AUTOSAR XML (schema 314)
package /ComponentType
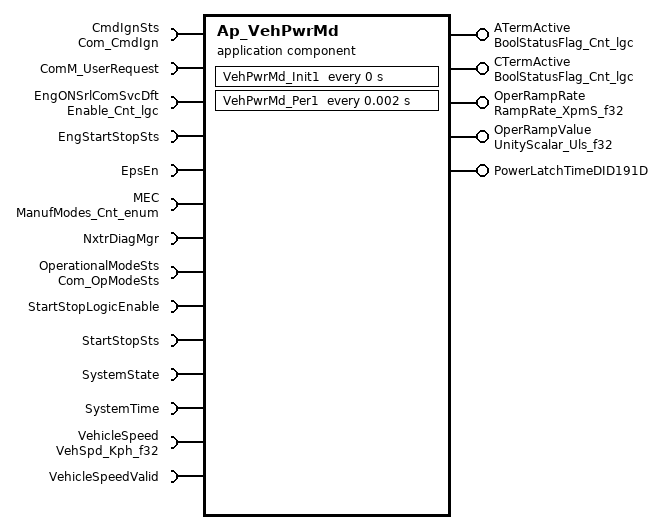
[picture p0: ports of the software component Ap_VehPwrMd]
  application software component type Ap_VehPwrMd
    5 x provide port:
      ATermActive: unqueued-sender-com-spec{data-element=Cnt_lgc, can-invalidate=false, init-value=D_TRUE_CNT_LGC}, provided-interface=BoolStatusFlag_Cnt_lgc
      CTermActive: unqueued-sender-com-spec{data-element=Cnt_lgc, can-invalidate=false, init-value=D_FALSE_CNT_LGC}, provided-interface=BoolStatusFlag_Cnt_lgc
      OperRampRate: unqueued-sender-com-spec{data-element=XpmS_f32, can-invalidate=false, init-value=D_ZERO_ULS_F32}, provided-interface=RampRate_XpmS_f32
      OperRampValue: unqueued-sender-com-spec{data-element=Uls_f32, can-invalidate=false, init-value=D_ZERO_ULS_F32}, provided-interface=UnityScalar_Uls_f32
      PowerLatchTimeDID191D: unqueued-sender-com-spec{data-element=Cnt_u16, can-invalidate=false, init-value=D_ZERO_CNT_U16}, provided-interface=PowerLatchTimeDID191D
    14 x require port:
      CmdIgnSts: unqueued-receiver-com-spec{data-element=Cnt_u16, init-value=C_CmdIgnSts}, required-interface=Com_CmdIgn
      ComM_UserRequest: required-com-specs=[GetCurrentComMode, GetMaxComMode, GetRequestedMode, RequestComMode], required-interface=ComM_UserRequest
      EngONSrlComSvcDft: unqueued-receiver-com-spec{data-element=Cnt_lgc, init-value=D_FALSE_CNT_LGC}, required-interface=Enable_Cnt_lgc
      EngStartStopSts: unqueued-receiver-com-spec{data-element=Cnt_u8, init-value=D_ZERO_CNT_U8}, required-interface=EngStartStopSts
      EpsEn: client-com-spec=OP_GET, required-interface=EpsEn
      MEC: unqueued-receiver-com-spec{data-element=Cnt_enum, init-value=D_MANUFMODEINIT_CNT_ENUM}, required-interface=ManufModes_Cnt_enum
      NxtrDiagMgr: required-com-specs=[GetNTCActive, GetNTCFailed, GetNTCStatus, SetNTCStatus], required-interface=NxtrDiagMgr
      OperationalModeSts: unqueued-receiver-com-spec{data-element=Cnt_u16, init-value=C_OperationalModeSts}, required-interface=Com_OpModeSts
      StartStopLogicEnable: unqueued-receiver-com-spec{data-element=Cnt_lgc, init-value=D_FALSE_CNT_LGC}, required-interface=StartStopLogicEnable
      StartStopSts: unqueued-receiver-com-spec{data-element=Cnt_u8, init-value=D_ZERO_CNT_U8}, required-interface=StartStopSts
      SystemState: required-interface=SystemState
      SystemTime: required-interface=SystemTime
        required-com-specs:
          DtrmnElapsedTime_mS_u16
          DtrmnElapsedTime_mS_u32
          DtrmnElapsedTime_uS_u16
          DtrmnElapsedTime_uS_u32
          GetSystemTime_mS_u32
          GetSystemTime_uS_u32
      VehicleSpeed: unqueued-receiver-com-spec{data-element=Kph_f32, init-value=D_ZERO_ULS_F32}, required-interface=VehSpd_Kph_f32
      VehicleSpeedValid: unqueued-receiver-com-spec{data-element=Cnt_lgc, init-value=D_FALSE_CNT_LGC}, required-interface=VehicleSpeedValid
  internal behavior Ap_VehPwrMd_InternalBehavior: component=Ap_VehPwrMd
    timing event VehPwrMd_Init1_InitEvent: start-on-event=VehPwrMd_Init1, period=0
    timing event TMT_VehPwrMd_Per1: start-on-event=VehPwrMd_Per1, period=0.002
    port-api-options:
      enable-take-address=false, indirect-api=false, port=ATermActive
      enable-take-address=false, indirect-api=false, port=CmdIgnSts
      enable-take-address=false, indirect-api=false, port=ComM_UserRequest
      enable-take-address=false, indirect-api=false, port=CTermActive
      enable-take-address=false, indirect-api=false, port=EngONSrlComSvcDft
      enable-take-address=false, indirect-api=false, port=EngStartStopSts
      enable-take-address=false, indirect-api=false, port=EpsEn
      enable-take-address=false, indirect-api=false, port=MEC
      enable-take-address=false, indirect-api=false, port=NxtrDiagMgr
      enable-take-address=false, indirect-api=false, port=OperationalModeSts
      enable-take-address=false, indirect-api=false, port=OperRampRate
      enable-take-address=false, indirect-api=false, port=OperRampValue
      enable-take-address=false, indirect-api=false, port=PowerLatchTimeDID191D
      enable-take-address=false, indirect-api=false, port=StartStopLogicEnable
      enable-take-address=false, indirect-api=false, port=StartStopSts
      enable-take-address=false, indirect-api=false, port=SystemState
      enable-take-address=false, indirect-api=false, port=SystemTime
      enable-take-address=false, indirect-api=false, port=VehicleSpeed
      enable-take-address=false, indirect-api=false, port=VehicleSpeedValid
    runnable VehPwrMd_Init1
      data write access WRITE_OperRampRate_XpmS_f32: data-element=OperRampRate.XpmS_f32
      data write access WRITE_OperRampValue_Uls_f32: data-element=OperRampValue.Uls_f32
      sync call SC_SystemTime_GetSystemTime_mS_u32: operation=SystemTime.GetSystemTime_mS_u32, timeout=0
    runnable VehPwrMd_Per1
      9 x data read access:
        READ_CmdIgnSts_Cnt_u16: data-element=CmdIgnSts.Cnt_u16
        READ_EngONSrlComSvcDft_Cnt_lgc: data-element=EngONSrlComSvcDft.Cnt_lgc
        READ_EngStartStopSts_Cnt_u8: data-element=EngStartStopSts.Cnt_u8
        READ_MEC_Cnt_enum: data-element=MEC.Cnt_enum
        READ_OperationalModeSts_Cnt_u16: data-element=OperationalModeSts.Cnt_u16
        READ_StartStopLogicEnable_Cnt_lgc: data-element=StartStopLogicEnable.Cnt_lgc
        READ_StartStopSts_Cnt_u8: data-element=StartStopSts.Cnt_u8
        READ_VehicleSpeed_Kph_f32: data-element=VehicleSpeed.Kph_f32
        READ_VehicleSpeedValid_Cnt_lgc: data-element=VehicleSpeedValid.Cnt_lgc
      5 x data write access:
        WRITE_ATermActive_Cnt_lgc: data-element=ATermActive.Cnt_lgc
        WRITE_CTermActive_Cnt_lgc: data-element=CTermActive.Cnt_lgc
        WRITE_OperRampRate_XpmS_f32: data-element=OperRampRate.XpmS_f32
        WRITE_OperRampValue_Uls_f32: data-element=OperRampValue.Uls_f32
        WRITE_PowerLatchTimeDID191D_Cnt_u16: data-element=PowerLatchTimeDID191D.Cnt_u16
      5 x sync call, all with timeout=0:
        SC_ComM_UserRequest_GetCurrentComMode: operation=ComM_UserRequest.GetCurrentComMode
        SC_EpsEn_OP_GET: operation=EpsEn.OP_GET
        SC_NxtrDiagMgr_GetNTCFailed: operation=NxtrDiagMgr.GetNTCFailed
        SC_SystemTime_DtrmnElapsedTime_mS_u16: operation=SystemTime.DtrmnElapsedTime_mS_u16
        SC_SystemTime_GetSystemTime_mS_u32: operation=SystemTime.GetSystemTime_mS_u32
  swc implementation Ap_VehPwrMd_Implementation: behavior=Ap_VehPwrMd_InternalBehavior
    code-descriptors:
      code Code: type=SRC
